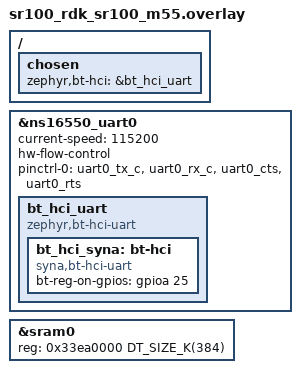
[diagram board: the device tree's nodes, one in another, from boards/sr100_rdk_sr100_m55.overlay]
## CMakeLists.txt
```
# Copyright (c) 2026 Synaptics Incorporated
#
# SPDX-License-Identifier: Apache-2.0

cmake_minimum_required(VERSION 3.20.0)

find_package(Zephyr REQUIRED HINTS $ENV{ZEPHYR_BASE})
project(bt_shell)

target_sources(app PRIVATE
  src/main.c
  src/syna_shell.c
)
```

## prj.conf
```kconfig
# Copyright (c) 2026 Synaptics Incorporated
#
# SPDX-License-Identifier: Apache-2.0

# ── Bluetooth ────────────────────────────────────────────────────────────────
CONFIG_BT=y
CONFIG_BT_PERIPHERAL=y
CONFIG_BT_CENTRAL=y
CONFIG_BT_SHELL=y

# ── Shell ────────────────────────────────────────────────────────────────────
CONFIG_SHELL=y
CONFIG_SHELL_BACKEND_SERIAL=y
CONFIG_SHELL_CMDS=y
CONFIG_SHELL_HELP=y
CONFIG_SHELL_HISTORY=y
CONFIG_SHELL_TAB=y

# ── Console ──────────────────────────────────────────────────────────────────
CONFIG_CONSOLE=y
CONFIG_UART_CONSOLE=y

# ── Logging ──────────────────────────────────────────────────────────────────
CONFIG_LOG=y
CONFIG_LOG_DEFAULT_LEVEL=1
CONFIG_LOG_PRINTK=y

CONFIG_LOG_MODE_DEFERRED=y
CONFIG_LOG_BUFFER_SIZE=16384
CONFIG_LOG_PROCESS_THREAD=y
CONFIG_LOG_PROCESS_THREAD_STACK_SIZE=2048

# ── SYNA hardware ────────────────────────────────────────────────────────────
CONFIG_BT_H4=y
CONFIG_BT_HCI_SYNA=y
CONFIG_BT_HCI_SYNA_BAUD_RATE=3000000
CONFIG_BT_4381=y
CONFIG_GPIO=y
CONFIG_REBOOT=y
CONFIG_UART_INTERRUPT_DRIVEN=y
CONFIG_UART_NS16550_VARIANT_NS16750=y

# ── Memory ───────────────────────────────────────────────────────────────────
CONFIG_MAIN_STACK_SIZE=4096
CONFIG_SYSTEM_WORKQUEUE_STACK_SIZE=4096
CONFIG_BT_RX_STACK_SIZE=4096
CONFIG_BT_BUF_CMD_TX_SIZE=255
CONFIG_BT_BUF_EVT_RX_SIZE=255

CONFIG_BT_HCI_CORE_LOG_LEVEL_ERR=y
CONFIG_BT_BUF_EVT_RX_COUNT=16
CONFIG_BT_BUF_EVT_DISCARDABLE_COUNT=32
CONFIG_BT_BUF_EVT_DISCARDABLE_SIZE=255
CONFIG_XIP=n
```

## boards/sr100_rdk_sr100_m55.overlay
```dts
/*
 * Copyright (c) 2026 Synaptics Incorporated
 *
 * SPDX-License-Identifier: Apache-2.0
 */

/ {
	chosen {
		zephyr,bt-hci = &bt_hci_uart;
	};
};

&ns16550_uart0 {
	status = "okay";
	current-speed = <115200>;
	hw-flow-control;
	pinctrl-0 = <&uart0_tx_c &uart0_rx_c &uart0_cts &uart0_rts>;
	pinctrl-names = "default";

	bt_hci_uart: bt_hci_uart {
		compatible = "zephyr,bt-hci-uart";
		status = "okay";

		bt_hci_syna: bt-hci {
			compatible = "syna,bt-hci-uart";
			status = "okay";
			bt-reg-on-gpios = <&gpioa 25 GPIO_ACTIVE_HIGH>;
		};
	};
};

&sram0 {
	reg = <0x33ea0000 DT_SIZE_K(384)>;
	ranges = <0x0 0x33ea0000 DT_SIZE_K(384)>;
};
```

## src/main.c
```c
/*
 * Copyright (c) 2026 Synaptics Incorporated
 *
 * SPDX-License-Identifier: Apache-2.0
 */

#include <zephyr/kernel.h>
#include <zephyr/shell/shell.h>

int main(void)
{
	/* Shell starts automatically via SYS_INIT.
	 * BT is initialised manually by the user with "bt init" from the shell.
	 * Nothing else needed here.
	 */
	return 0;
}
```

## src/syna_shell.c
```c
/*
 * Copyright (c) 2026 Synaptics Incorporated
 *
 * SPDX-License-Identifier: Apache-2.0
 */

#include <zephyr/kernel.h>
#include <zephyr/shell/shell.h>
#include <zephyr/sys/reboot.h>
#include <zephyr/sys/sys_io.h>
#include <zephyr/sys/barrier.h>
#include <zephyr/drivers/gpio.h>
#include <zephyr/device.h>
#include <stdlib.h>

/*
 * AON POR mask register (0x50350038):
 *   Clearing bit 11 (AON_POR_RST_EVENT_SW_RESET_MASK) allows SW_RESET
 *   event to trigger a full SoC POR reset.
 */
#define SR100_AON_POR_MASK         0x50350038UL
#define AON_POR_SW_RESET_BIT       11

/* Global reset trigger (0x50330600): write 1 to trigger immediate SoC reset */
#define SR100_GLOBAL_RST_TRIGGER   0x50330600UL

/*
 * AON memory BCM_AON_GP_SW_Cache (0x50352030):
 *   If this equals BCM_SPK_FAIL_MAGIC after reset, the APBL skips flash
 *   boot and enters External Host (ROM download) mode.
 */
#define SR100_BCM_AON_GP_SW_CACHE  0x50352030UL
#define BCM_SPK_FAIL_MAGIC         0x6662666FUL

/* ---- reboot ---- */

static int cmd_reboot(const struct shell *sh, size_t argc, char *argv[])
{
	shell_print(sh, "Rebooting...");
	k_sleep(K_MSEC(100)); /* flush shell output before reboot */
	sys_reboot(SYS_REBOOT_COLD);
	return 0;
}

SHELL_CMD_REGISTER(reboot, NULL, "Reboot the device", cmd_reboot);

/* ---- reboot_rom ---- */

static int cmd_reboot_rom(const struct shell *sh, size_t argc, char *argv[])
{
	shell_print(sh, "Rebooting to ROM download mode...");
	k_sleep(K_MSEC(100));

	/* Signal APBL to enter External Host (download) mode after reset */
	sys_write32(BCM_SPK_FAIL_MAGIC, SR100_BCM_AON_GP_SW_CACHE);

	barrier_dmem_fence_full();

	/* Trigger chip reset */
	sys_write32(1U, SR100_GLOBAL_RST_TRIGGER);

	while (1) {
	}

	CODE_UNREACHABLE;
	return 0;
}

SHELL_CMD_REGISTER(reboot_rom, NULL,
	"Reboot to ROM download mode (SoC POR reset)", cmd_reboot_rom);

/* ---- build_info ---- */

static int cmd_build_info(const struct shell *sh, size_t argc, char *argv[])
{
	shell_print(sh, "Build: %s %s", __DATE__, __TIME__);
	return 0;
}

SHELL_CMD_REGISTER(build_info, NULL, "Show firmware build date/time", cmd_build_info);

/* ---- GPIO control ---- */

static const struct device *const gpioa_dev = DEVICE_DT_GET(DT_NODELABEL(gpioa));

/*
 * gpio <pin> <0|1>  — configure gpioa pin as output and drive low/high
 * gpio <pin>        — configure gpioa pin as input and read current value
 *
 * Examples:
 *   gpio 25 1   -> drive GPIO25 high
 *   gpio 25 0   -> drive GPIO25 low
 *   gpio 25     -> read GPIO25
 */
static int cmd_gpio_ctrl(const struct shell *sh, size_t argc, char *argv[])
{
	if (!device_is_ready(gpioa_dev)) {
		shell_error(sh, "gpioa device not ready");
		return -ENODEV;
	}

	char *end;
	long pin = strtol(argv[1], &end, 10);

	if (*end != '\0' || pin < 0 || pin > 31) {
		shell_error(sh, "Invalid pin: %s (0-31)", argv[1]);
		return -EINVAL;
	}

	/* Read mode: gpio <pin> */
	if (argc == 2) {
		int ret = gpio_pin_configure(gpioa_dev, (gpio_pin_t)pin, GPIO_INPUT);

		if (ret < 0) {
			shell_error(sh, "Configure GPIO%ld as input failed: %d", pin, ret);
			return ret;
		}
		int val = gpio_pin_get(gpioa_dev, (gpio_pin_t)pin);

		if (val < 0) {
			shell_error(sh, "Read GPIO%ld failed: %d", pin, val);
			return val;
		}
		shell_print(sh, "GPIO%ld = %d", pin, val);
		return 0;
	}

	/* Write mode: gpio <pin> <0|1> */
	long val = strtol(argv[2], &end, 10);

	if (*end != '\0' || (val != 0 && val != 1)) {
		shell_error(sh, "Invalid value: %s (use 0 or 1)", argv[2]);
		return -EINVAL;
	}

	int ret = gpio_pin_configure(gpioa_dev, (gpio_pin_t)pin, GPIO_OUTPUT);

	if (ret < 0) {
		shell_error(sh, "Configure GPIO%ld as output failed: %d", pin, ret);
		return ret;
	}

	ret = gpio_pin_set(gpioa_dev, (gpio_pin_t)pin, (int)val);
	if (ret < 0) {
		shell_error(sh, "Set GPIO%ld failed: %d", pin, ret);
		return ret;
	}

	shell_print(sh, "GPIO%ld -> %ld", pin, val);
	return 0;
}

SHELL_CMD_ARG_REGISTER(gpio, NULL,
	"Control/read gpioa pin\n"
	"  gpio <pin> <0|1>  set output\n"
	"  gpio <pin>        read input",
	cmd_gpio_ctrl, 2, 1);
```
